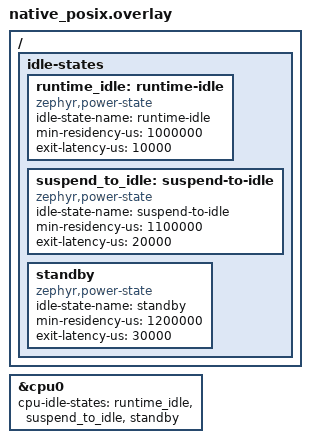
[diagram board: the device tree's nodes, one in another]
/*
 * Copyright (c) 2022 Nordic Semiconductor ASA
 * SPDX-License-Identifier: Apache-2.0
 */

/ {
	idle-states {
		runtime_idle: runtime-idle {
			compatible = "zephyr,power-state";
			idle-state-name = "runtime-idle";
			min-residency-us = <1000000>;
			exit-latency-us = <10000>;
		};
		suspend_to_idle: suspend-to-idle {
			compatible = "zephyr,power-state";
			idle-state-name = "suspend-to-idle";
			min-residency-us = <1100000>;
			exit-latency-us = <20000>;
		};
		standby: standby {
			compatible = "zephyr,power-state";
			idle-state-name = "standby";
			min-residency-us = <1200000>;
			exit-latency-us = <30000>;
		};
	};
};

&cpu0 {
	cpu-idle-states = <&runtime_idle &suspend_to_idle &standby>;
};
